# ioam3358 register map
Registers are 32-bit, access not given, no defined reset value unless marked. A register's access mark holds for its fields unless they carry their own. Addresses are absolute; registers are grouped by the start of their names; [hi:lo] are bit positions; {n}, {i} and the like mark numbered series; 'fields as' and 'values as' point back to an identical list.

## CLKSEL
0x44E00504 CLKSEL_TIMER7_CLK
  [1:0] CLKSEL
{0x44E00500+4i} CLKSEL_TIMER{i}_CLK (i=2..4)
  [1:0] CLKSEL
0x44E00518 CLKSEL_TIMER5_CLK
  [1:0] CLKSEL
0x44E0051C CLKSEL_TIMER6_CLK
  [1:0] CLKSEL
0x44E00528 CLKSEL_TIMER1MS_CLK
  [2:0] CLKSEL
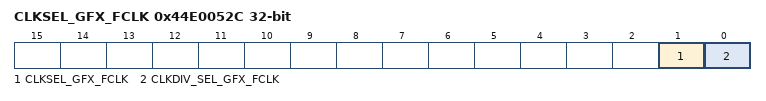
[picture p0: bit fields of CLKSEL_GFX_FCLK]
0x44E0052C CLKSEL_GFX_FCLK
  [1] CLKSEL_GFX_FCLK, [0] CLKDIV_SEL_GFX_FCLK
0x44E00530 CLKSEL_PRU_ICSS_OCP_CLK
  [0] CLKSEL
0x44E00534 CLKSEL_LCDC_PIXEL_CLK
  [1:0] CLKSEL
0x44E00538 CLKSEL_WDT1_CLK
  [0] CLKSEL
0x44E0053C CLKSEL_GPIO0_DBCLK
  [1:0] CLKSEL

## PRM
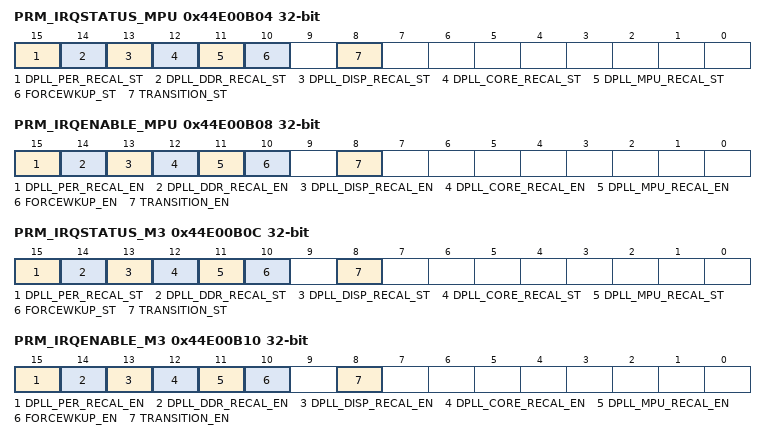
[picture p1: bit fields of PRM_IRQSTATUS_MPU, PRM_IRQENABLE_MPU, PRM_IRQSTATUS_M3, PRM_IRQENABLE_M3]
0x44E00B04 PRM_IRQSTATUS_MPU
  [15] DPLL_PER_RECAL_ST, [14] DPLL_DDR_RECAL_ST, [13] DPLL_DISP_RECAL_ST, [12] DPLL_CORE_RECAL_ST, [11] DPLL_MPU_RECAL_ST, [10] FORCEWKUP_ST, [8] TRANSITION_ST
0x44E00B08 PRM_IRQENABLE_MPU
  [15] DPLL_PER_RECAL_EN, [14] DPLL_DDR_RECAL_EN, [13] DPLL_DISP_RECAL_EN, [12] DPLL_CORE_RECAL_EN, [11] DPLL_MPU_RECAL_EN, [10] FORCEWKUP_EN, [8] TRANSITION_EN
0x44E00B0C PRM_IRQSTATUS_M3
  fields as PRM_IRQSTATUS_MPU
0x44E00B10 PRM_IRQENABLE_M3
  fields as PRM_IRQENABLE_MPU
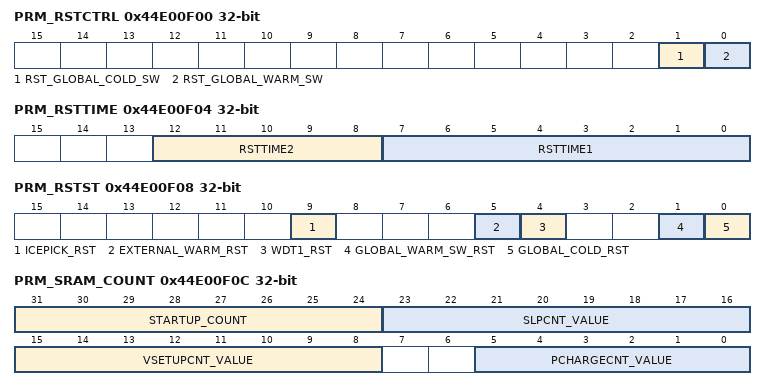
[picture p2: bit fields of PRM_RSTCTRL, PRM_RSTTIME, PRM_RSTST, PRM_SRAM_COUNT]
0x44E00F00 PRM_RSTCTRL
  [1] RST_GLOBAL_COLD_SW, [0] RST_GLOBAL_WARM_SW
0x44E00F04 PRM_RSTTIME
  [12:8] RSTTIME2, [7:0] RSTTIME1
0x44E00F08 PRM_RSTST
  [9] ICEPICK_RST, [5] EXTERNAL_WARM_RST, [4] WDT1_RST, [1] GLOBAL_WARM_SW_RST, [0] GLOBAL_COLD_RST
0x44E00F0C PRM_SRAM_COUNT
  [31:24] STARTUP_COUNT, [23:16] SLPCNT_VALUE, [15:8] VSETUPCNT_VALUE, [5:0] PCHARGECNT_VALUE
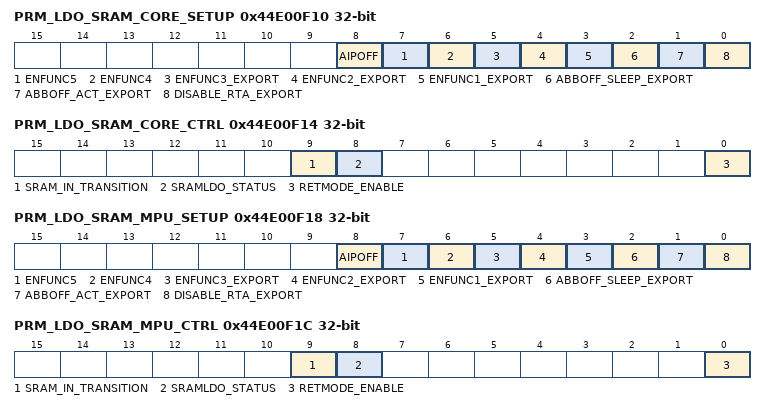
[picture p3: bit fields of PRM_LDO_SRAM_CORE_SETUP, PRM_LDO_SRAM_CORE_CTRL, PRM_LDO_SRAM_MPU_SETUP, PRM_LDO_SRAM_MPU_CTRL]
0x44E00F10 PRM_LDO_SRAM_CORE_SETUP
  [8] AIPOFF, [7] ENFUNC5, [6] ENFUNC4, [5] ENFUNC3_EXPORT, [4] ENFUNC2_EXPORT, [3] ENFUNC1_EXPORT, [2] ABBOFF_SLEEP_EXPORT, [1] ABBOFF_ACT_EXPORT, [0] DISABLE_RTA_EXPORT
0x44E00F14 PRM_LDO_SRAM_CORE_CTRL
  [9] SRAM_IN_TRANSITION, [8] SRAMLDO_STATUS, [0] RETMODE_ENABLE
0x44E00F18 PRM_LDO_SRAM_MPU_SETUP
  fields as PRM_LDO_SRAM_CORE_SETUP
0x44E00F1C PRM_LDO_SRAM_MPU_CTRL
  [9] SRAM_IN_TRANSITION, [8] SRAMLDO_STATUS, [0] RETMODE_ENABLE

## RM
0x44E00C00 RM_PER_RSTCTRL
  [1] PRU_ICSS_LRST
0x44E00D00 RM_WKUP_RSTCTRL
  [3] WKUP_M3_LRST
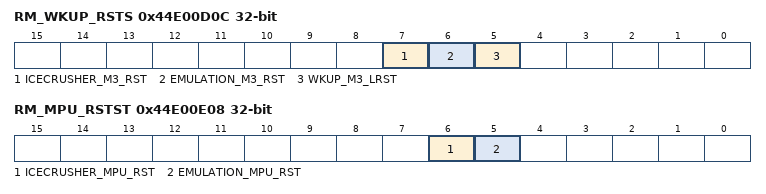
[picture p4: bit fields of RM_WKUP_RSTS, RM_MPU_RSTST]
0x44E00D0C RM_WKUP_RSTS
  [7] ICECRUSHER_M3_RST, [6] EMULATION_M3_RST, [5] WKUP_M3_LRST
0x44E00E08 RM_MPU_RSTST
  [6] ICECRUSHER_MPU_RST, [5] EMULATION_MPU_RST
0x44E01104 RM_GFX_RSTCTRL
  [0] GFX_RST
0x44E01114 RM_GFX_RSTST
  [0] GFX_RST

## PM
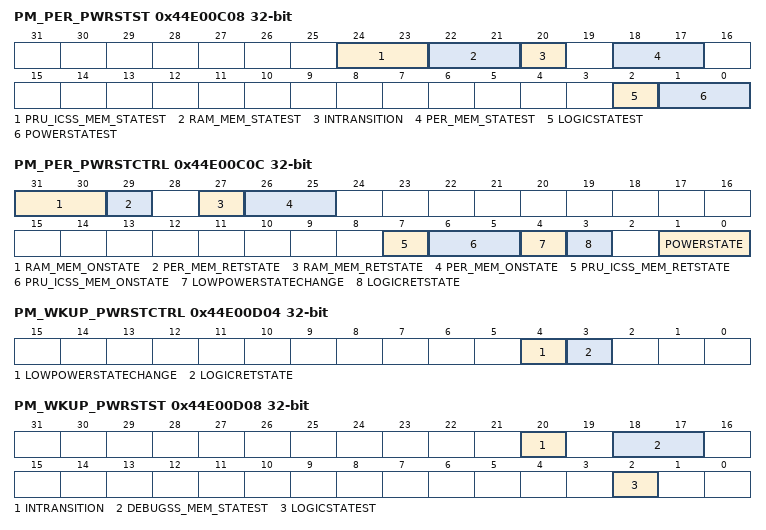
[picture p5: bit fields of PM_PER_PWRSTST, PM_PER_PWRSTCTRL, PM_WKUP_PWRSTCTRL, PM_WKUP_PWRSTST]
0x44E00C08 PM_PER_PWRSTST
  [24:23] PRU_ICSS_MEM_STATEST, [22:21] RAM_MEM_STATEST, [20] INTRANSITION, [18:17] PER_MEM_STATEST, [2] LOGICSTATEST, [1:0] POWERSTATEST
0x44E00C0C PM_PER_PWRSTCTRL
  [31:30] RAM_MEM_ONSTATE, [29] PER_MEM_RETSTATE, [27] RAM_MEM_RETSTATE, [26:25] PER_MEM_ONSTATE, [7] PRU_ICSS_MEM_RETSTATE, [6:5] PRU_ICSS_MEM_ONSTATE, [4] LOWPOWERSTATECHANGE, [3] LOGICRETSTATE, [1:0] POWERSTATE
0x44E00D04 PM_WKUP_PWRSTCTRL
  [4] LOWPOWERSTATECHANGE, [3] LOGICRETSTATE
0x44E00D08 PM_WKUP_PWRSTST
  [20] INTRANSITION, [18:17] DEBUGSS_MEM_STATEST, [2] LOGICSTATEST
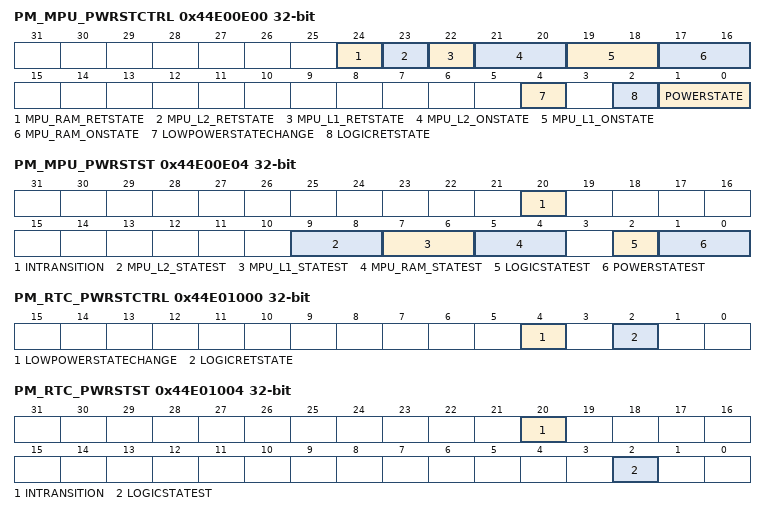
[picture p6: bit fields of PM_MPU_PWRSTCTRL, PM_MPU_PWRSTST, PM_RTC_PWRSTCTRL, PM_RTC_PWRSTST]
0x44E00E00 PM_MPU_PWRSTCTRL
  [24] MPU_RAM_RETSTATE, [23] MPU_L2_RETSTATE, [22] MPU_L1_RETSTATE, [21:20] MPU_L2_ONSTATE, [19:18] MPU_L1_ONSTATE, [17:16] MPU_RAM_ONSTATE, [4] LOWPOWERSTATECHANGE, [2] LOGICRETSTATE, [1:0] POWERSTATE
0x44E00E04 PM_MPU_PWRSTST
  [20] INTRANSITION, [9:8] MPU_L2_STATEST, [7:6] MPU_L1_STATEST, [5:4] MPU_RAM_STATEST, [2] LOGICSTATEST, [1:0] POWERSTATEST
0x44E01000 PM_RTC_PWRSTCTRL
  [4] LOWPOWERSTATECHANGE, [2] LOGICRETSTATE
0x44E01004 PM_RTC_PWRSTST
  [20] INTRANSITION, [2] LOGICSTATEST
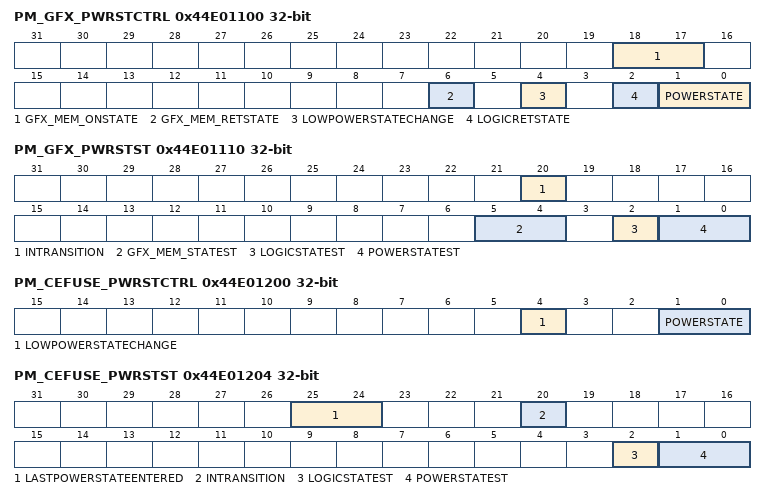
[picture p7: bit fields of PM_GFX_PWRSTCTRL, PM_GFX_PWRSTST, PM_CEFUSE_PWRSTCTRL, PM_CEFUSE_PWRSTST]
0x44E01100 PM_GFX_PWRSTCTRL
  [18:17] GFX_MEM_ONSTATE, [6] GFX_MEM_RETSTATE, [4] LOWPOWERSTATECHANGE, [2] LOGICRETSTATE, [1:0] POWERSTATE
0x44E01110 PM_GFX_PWRSTST
  [20] INTRANSITION, [5:4] GFX_MEM_STATEST, [2] LOGICSTATEST, [1:0] POWERSTATEST
0x44E01200 PM_CEFUSE_PWRSTCTRL
  [4] LOWPOWERSTATECHANGE, [1:0] POWERSTATE
0x44E01204 PM_CEFUSE_PWRSTST
  [25:24] LASTPOWERSTATEENTERED, [20] INTRANSITION, [2] LOGICSTATEST, [1:0] POWERSTATEST
